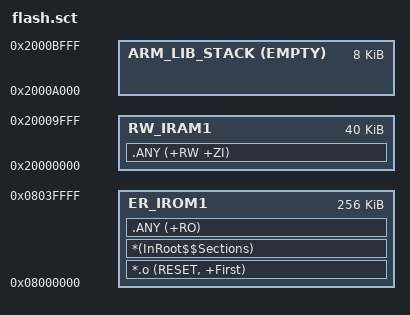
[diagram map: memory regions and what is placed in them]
; 与 GCC 工程保持相同的 Flash 范围、栈顶和 8 KiB 栈预留。
LR_IROM1 0x08000000 0x40000 {
    ER_IROM1 0x08000000 0x40000 {
        *.o (RESET, +First)
        *(InRoot$$Sections)
        .ANY (+RO)
    }
    RW_IRAM1 0x20000000 0xA000 {
        .ANY (+RW +ZI)
    }
    ARM_LIB_STACK 0x2000A000 EMPTY 0x2000 {}
}
